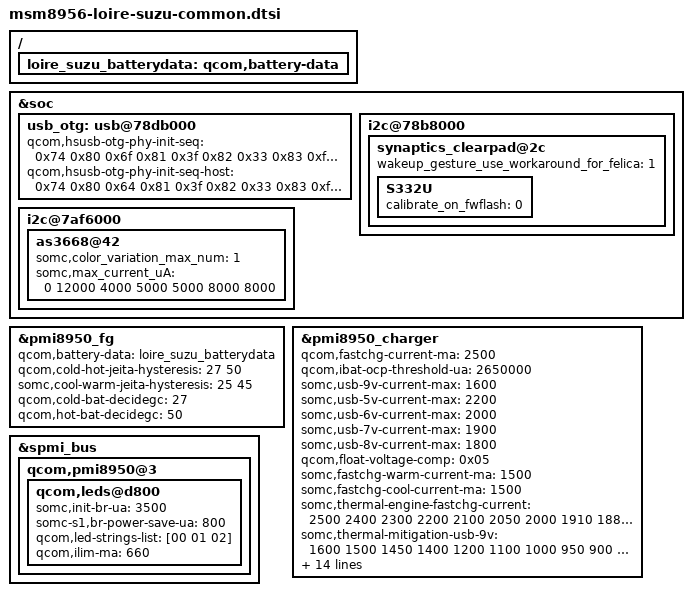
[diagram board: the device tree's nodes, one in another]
/* arch/arm/boot/dts/qcom/msm8956-loire-suzu-common.dtsi
 *
 * This program is free software; you can redistribute it and/or modify
 * it under the terms of the GNU General Public License version 2 and
 * only version 2 as published by the Free Software Foundation.
 *
 * This program is distributed in the hope that it will be useful,
 * but WITHOUT ANY WARRANTY; without even the implied warranty of
 * MERCHANTABILITY or FITNESS FOR A PARTICULAR PURPOSE.  See the
 * GNU General Public License for more details.
 */
/*
 * Copyright (C) 2015 Sony Mobile Communications Inc.
 *
 * This program is free software; you can redistribute it and/or modify
 * it under the terms of the GNU General Public License version 2, as
 * published by the Free Software Foundation.
 */

&soc {
	usb_otg: usb@78db000 {
		qcom,hsusb-otg-phy-init-seq =
			<0x74 0x80 0x6f 0x81 0x3f 0x82 0x33 0x83 0xffffffff>;
		qcom,hsusb-otg-phy-init-seq-host =
			<0x74 0x80 0x64 0x81 0x3f 0x82 0x33 0x83 0xffffffff>;
	};

	/* I2C : BLSP4 */
	i2c@78b8000 { /* BLSP1 QUP3 */
		synaptics_clearpad@2c {
			wakeup_gesture_use_workaround_for_felica = <1>;
			/* chip settings */
			S332U {
				calibrate_on_fwflash = <0>;
			};
		};
	};
	/* I2C : BLSP6 */
	i2c@7af6000 { /* BLSP2 QUP1 */
		as3668@42 {
			somc,color_variation_max_num = <1>;
			somc,max_current_uA = <0 12000 4000 5000 5000 8000 8000>;
		};
	};
};

/{
	loire_suzu_batterydata: qcom,battery-data {
		#include "batterydata-loire-suzu-send.dtsi"
		#include "batterydata-loire-suzu-atl.dtsi"
	};
};

&pmi8950_fg {
	qcom,battery-data = <&loire_suzu_batterydata>;
	qcom,cold-hot-jeita-hysteresis = <27 50>;
	somc,cool-warm-jeita-hysteresis = <25 45>;
	qcom,cold-bat-decidegc = <27>;
	qcom,hot-bat-decidegc = <50>;
};

&pmi8950_charger {
	qcom,fastchg-current-ma = <2500>;
	qcom,ibat-ocp-threshold-ua = <2650000>;
	somc,usb-9v-current-max = <1600>;
	somc,usb-5v-current-max = <2200>;
	somc,usb-6v-current-max = <2000>;
	somc,usb-7v-current-max = <1900>;
	somc,usb-8v-current-max = <1800>;
	qcom,float-voltage-comp = <0x05>;
	somc,fastchg-warm-current-ma = <1500>;
	somc,fastchg-cool-current-ma = <1500>;
	somc,thermal-engine-fastchg-current = <2500 2400 2300 2200 2100 2050 2000 1910 1880 1850 1800 1600 1500 1400 1200>;
	somc,thermal-mitigation-usb-9v = <1600 1500 1450 1400 1200 1100 1000 950 900 700 650 600 550 500 475>;
	somc,thermal-mitigation-usb-8v = <1800 1700 1600 1500 1400 1400 1200 1100 1100 900 700 500 500 500 500>;
	somc,thermal-mitigation-usb-7v = <1900 1800 1700 1700 1600 1500 1400 1200 1100 900 700 500 500 500 500>;
	somc,thermal-mitigation-usb-6v = <2000 1900 1800 1700 1600 1500 1400 1200 1100 900 700 500 500 500 500>;
	somc,thermal-mitigation-usb-5v = <2200 2100 2050 2000 1900 1800 1600 1500 1400 1200 1100 1000 900 700 500>;
	somc,limit-usb-5v-level = <15>;
	qcom,autoadjust-vfloat;
	qcom,auto-voltage-comp-mv = <30>;
	qcom,rparasitics-uohm = <127500>;
	qcom,dc-psy-type = "Mains";
	qcom,dc-psy-ma = <2200>;
};

&spmi_bus {
	qcom,pmi8950@3 {
		qcom,leds@d800 {
			somc,init-br-ua = <3500>;
			somc-s1,br-power-save-ua = <800>;
			qcom,led-strings-list = [00 01 02];
			qcom,ilim-ma = <660>;
		};
	};
};
